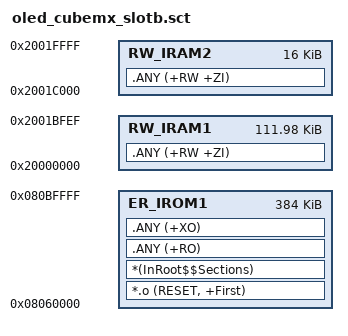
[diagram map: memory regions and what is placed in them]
; *************************************************************
; *** APP Slot B Scatter File — ROM: 0x08060000, 384KB (S7~S9)
; *************************************************************

LR_IROM1 0x08060000 0x00060000  {    ; load region size_region (384KB)
  ER_IROM1 0x08060000 0x00060000  {  ; load address = execution address
    *.o (RESET, +First)
    *(InRoot$$Sections)
    .ANY (+RO)
    .ANY (+XO)
  }
  RW_IRAM1 0x20000000 0x0001BFF0  {  ; RW data (112KB - 16B NOINIT)
    .ANY (+RW +ZI)
  }
  RW_IRAM2 0x2001C000 0x00004000  {
    .ANY (+RW +ZI)
  }
}
